AUTOSAR XML (schema 4-3-0)
standard types defined: boolean, float32, sint32, uint32, boolean_CompuMethod, boolean_DataConstr, float32_DataConstr, sint32_DataConstr, uint32_DataConstr, uint8, uint8_DataConstr
package /ASP_Constants
  constant specification LKA_Core_OutputConstant: value-spec=fields=[{short-label=lka, fields=[status:0, {short-label=available, fields=[left:0, right:0]}, {short-label=suppressionReason, fields=[left:0, right:0]}]}, {short-label=ldw, fields=[warningSide:0, status:0, {short-label=available, fields=[left:0, right:0]}, {short-label=suppressionReason, fields=[left:0, right:0]}]}, {short-label=roadEdge, fields=[status:0, {short-label=available, fields=[left:0, right:0]}, {short-label=suppressionReason, fields=[left:0, right:0]}]}, {short-label=lkaController, fields=[mode:0, interventionSide:0, torqueDirectionLimit:0, abortReason:0]}, {short-label=lkaLatController, fields=[frontWheelAngleRequest:0, lowerTorqueLimit:0, upperTorqueLimit:0]}]
package /ASP_DataTypes
  10 x impl type:
    As_LDW_Output: category=STRUCTURE
      4 x element, all with category=TYPE_REFERENCE:
        warningSide: implementation-data-type=As_LKA_Side
        status: implementation-data-type=As_LKA_Status
        available: implementation-data-type=As_LKA_SideStatus
        suppressionReason: implementation-data-type=As_SuppressionReason
    As_LKA_Controller_Output: category=STRUCTURE
      4 x element, all with category=TYPE_REFERENCE:
        mode: implementation-data-type=As_LKA_Core_Mode
        interventionSide: implementation-data-type=As_LKA_Side
        torqueDirectionLimit: implementation-data-type=As_LKA_Side
        abortReason: implementation-data-type=uint32
    As_LKA_Core_Mode: compu {0=As_LKA_Core_Mode_NONE, 1=As_LKA_Core_Mode_LKA, 2=As_LKA_Core_Mode_ELKA_ROAD_EDGE, 3=As_LKA_Core_Mode_ELKA_ONCOMING, 4=As_LKA_Core_Mode_ELKA_BLIS, 5=As_LKA_Core_Mode_ELKA_VRU}, implementation-data-type=sint32
    As_LKA_Core_Output: category=STRUCTURE
      5 x element, all with category=TYPE_REFERENCE:
        lka: implementation-data-type=As_LKA_Output
        ldw: implementation-data-type=As_LDW_Output
        roadEdge: implementation-data-type=As_LKA_Output
        lkaController: implementation-data-type=As_LKA_Controller_Output
        lkaLatController: implementation-data-type=As_LKA_LatControl_Output
    As_LKA_LatControl_Output: category=STRUCTURE
      element frontWheelAngleRequest: implementation-data-type=float32
      element lowerTorqueLimit: implementation-data-type=float32
      element upperTorqueLimit: implementation-data-type=float32
    As_LKA_Output: category=STRUCTURE
      element status: implementation-data-type=As_LKA_Status
      element available: implementation-data-type=As_LKA_SideStatus
      element suppressionReason: implementation-data-type=As_SuppressionReason
    As_LKA_Side: compu {0=As_LKA_Side_NONE, 1=As_LKA_Side_LEFT, 2=As_LKA_Side_RIGHT}, implementation-data-type=sint32
    As_LKA_SideStatus: category=STRUCTURE
      element left: implementation-data-type=boolean
      element right: implementation-data-type=boolean
    As_LKA_Status: compu {0=As_LKA_Status_DISABLED, 1=As_LKA_Status_UNAVAILABLE, 2=As_LKA_Status_AVAILABLE}, implementation-data-type=sint32
    As_SuppressionReason: category=STRUCTURE
      element left: implementation-data-type=uint32
      element right: implementation-data-type=uint32
package /ASP_PortInterfaces
  sender receiver interface LKA_OutputPort: invalidation-policy{data-element=LKAoutput, handle-invalid=DONT-INVALIDATE}
    data LKAoutput: type=As_LKA_Core_Output
package /ComponentTypes/LkaAdapSWC
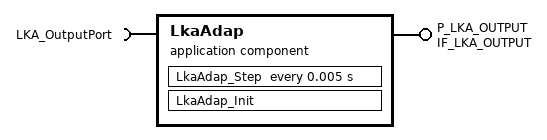
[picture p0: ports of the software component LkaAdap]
  application sw component type LkaAdap
    provide port P_LKA_OUTPUT: nonqueued-sender-com-spec{data-element=DE_LKA_OUTPUT, init-value=constant-reference=CS_LKA_OUTPUT}, provided-interface=IF_LKA_OUTPUT
    require port LKA_OutputPort: nonqueued-receiver-com-spec{data-element=LKAoutput, filter=data-filter-type=ALWAYS, init-value=constant-reference=LKA_Core_OutputConstant}, required-interface=LKA_OutputPort
    behavior LkaAdap_InternalBehavior
      init event LkaAdap_InitEvent: start-on-event=LkaAdap_Init
      timing event LkaAdap_Step_TE: start-on-event=LkaAdap_Step, period=0.005
      runnable LkaAdap_Init
        data-receive-point-by-arguments:
          access REC_LKA_OutputPort_LKAoutput: accessed-variable=LKA_OutputPort.LKAoutput
        data-send-points:
          access SEND_P_LKA_OUTPUT_DE_LKA_OUTPUT: accessed-variable=P_LKA_OUTPUT.DE_LKA_OUTPUT
      runnable LkaAdap_Step
        data-receive-point-by-arguments:
          access REC_LKA_OutputPort_LKAoutput: accessed-variable=LKA_OutputPort.LKAoutput
        data-send-points:
          access SEND_P_LKA_OUTPUT_DE_LKA_OUTPUT: accessed-variable=P_LKA_OUTPUT.DE_LKA_OUTPUT
  swc implementation LkaAdap_Implementation: behavior=LkaAdap_InternalBehavior
    code-descriptors:
      code Default: artifact-descriptors=autosar-engineering-object={short-label=Default, category=SWSRC}
package /ComponentTypes/LkaAdapSWC/Constants
  constant specification CS_LKA_OUTPUT: value-spec=fields=[LKA_OptUsmSta_Copy_1:0, LKA_LHLnWrnSta_Copy_1:0, LKA_RHLnWrnSta_Copy_1:0]
package /ComponentTypes/LkaAdapSWC/DataTypes
  impl type LKA_OUTPUTS_T: category=STRUCTURE, type-emitter=RTE
    element LKA_OptUsmSta_Copy_1: implementation-data-type=uint8
    element LKA_LHLnWrnSta_Copy_1: implementation-data-type=uint8
    element LKA_RHLnWrnSta_Copy_1: implementation-data-type=uint8
package /ComponentTypes/LkaAdapSWC/PortInterfaces
  sender receiver interface IF_LKA_OUTPUT: invalidation-policy{data-element=DE_LKA_OUTPUT, handle-invalid=DONT-INVALIDATE}
    data DE_LKA_OUTPUT: type=LKA_OUTPUTS_T
